AUTOSAR XML (schema 321)
package /ComponentType
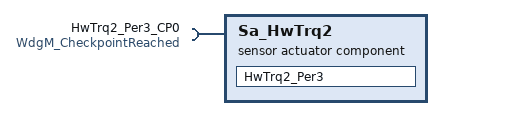
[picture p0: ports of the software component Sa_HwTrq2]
  sensor actuator software component type Sa_HwTrq2
    require port HwTrq2_Per3_CP0: client-com-spec=CheckpointReached, required-interface=WdgM_CheckpointReached
  internal behavior Sa_HwTrq2_InternalBehavior: component=Sa_HwTrq2, port-api-option{enable-take-address=false, indirect-api=false, port=HwTrq2_Per3_CP0}
    runnable HwTrq2_Per3
      sync call SC_HwTrq2_Per3_CP0_CheckpointReached: operation=HwTrq2_Per3_CP0.CheckpointReached, timeout=0
  swc implementation Sa_HwTrq2_Implementation: behavior=Sa_HwTrq2_InternalBehavior
    code-descriptors:
      code Code: type=SRC
package /PortInterface
  client server interface WdgM_CheckpointReached: is-service=true
    operation CheckpointReached: possible-error=E_NOT_OK  # Indicates to the Watchdog Manager that a Checkpoint within a Supervised Entity has been reached.
    error E_NOT_OK: error-code=1
